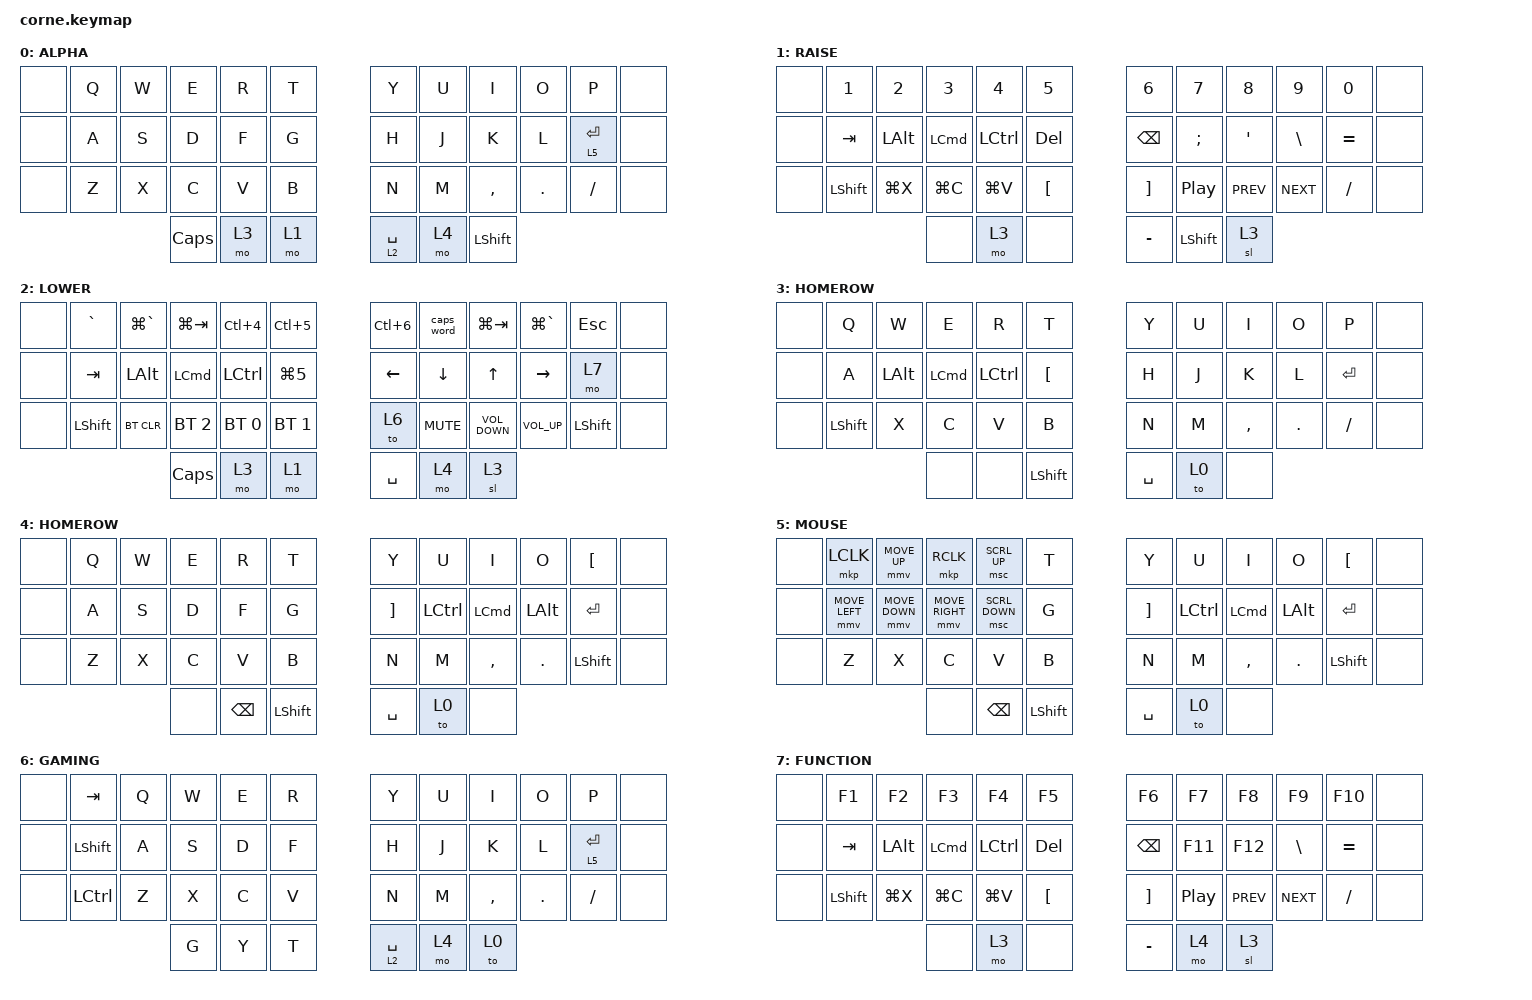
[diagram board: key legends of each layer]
#include <behaviors.dtsi>
#include <dt-bindings/zmk/keys.h>
#include <dt-bindings/zmk/bt.h>

#define ZMK_POINTING_DEFAULT_MOVE_VAL 1500  // default: 600
#define ZMK_POINTING_DEFAULT_SCRL_VAL 20
#include <dt-bindings/zmk/pointing.h>
#include <dt-bindings/zmk/ext_power.h>

#define L0 0
#define L1 1
#define L2 2
#define L3 3
#define L4 4
#define L5 5
#define L6 6
#define L7 7

#define KEYS_L 0 1 2 3 4 5 12 13 14 15 16 17 24 25 26 27 28 29 36 37 38
#define KEYS_R 6 7 8 9 10 11 18 19 20 21 22 23 30 31 32 33 34 35 39 40 41

/ { 
  keymap {
    compatible = "zmk,keymap";

    /**
     * Alpha layer (L0)
     */
    layer_0 {
      label = "ALPHA";
      bindings = <
        &none &kp Q     &kp W       &kp E       &kp R        &kp T       &kp Y      &kp U        &kp I       &kp O       &kp P     &none
        &none &kp A     &kp S       &kp D       &kp F        &kp G       &kp H      &kp J        &kp K       &kp L       &lt L5 RET   &none
        &none &kp Z     &kp X       &kp C       &kp V        &kp B       &kp N      &kp M        &kp COMMA   &kp DOT     &kp FSLH  &none
                                    &kp CAPS    &mo L3       &mo L1      &lt L2 SPACE &mo L4  &kp LSHIFT
      >;
    };

    /**
     * Symbols layer (L1)
     */
    layer_1 {
      label = "RAISE";
      bindings = <
        &none &kp N1   &kp N2    &kp N3    &kp N4     &kp N5     &kp N6    &kp N7    &kp N8    &kp N9            &kp N0    &none
        &none &kp TAB  &kp LALT  &kp LCMD  &kp LCTRL  &kp DEL   &kp BSPC  &kp SEMI  &kp SQT   &kp BSLH      &kp EQUAL &none
        &none &kp LSHIFT &kp LG(X) &kp LG(C) &kp LG(V)  &kp LBKT &kp RBKT  &kp C_PP &kp C_PREV  &kp C_NEXT &kp FSLH  &none
                                 &none     &mo L3     &none      &kp MINUS &kp LSHIFT  &sl L3
      >;
    };

    /**
     * Number and directions layer (L2)
     */
    layer_2 {
      label = "LOWER";
      bindings = <
        &none &kp GRAVE &kp LG(GRAVE)  &kp LG(TAB)  &kp LC(N4)  &kp LC(N5)  &kp LC(N6)  &caps_word &kp LG(TAB) &kp LG(GRAVE)  &kp ESC &none
        &none &kp TAB &kp LALT  &kp LCMD  &kp LCTRL  &kp LG(N5)  &kp LEFT &kp DOWN &kp UP  &kp RIGHT  &mo L7    &none
        &none &kp LSHIFT  &bt BT_CLR &bt BT_SEL 2  &bt BT_SEL 0  &bt BT_SEL 1   &to L6   &kp C_MUTE &kp C_VOLUME_DOWN &kp C_VOLUME_UP &kp LSHIFT  &none
                  &kp CAPS  &mo L3     &mo L1      &kp SPACE &mo L4       &sl L3
      >;
    };

    /**
     * Controls homerow mod (L3)
     */
    layer_3 {
      label = "HOMEROW";
      bindings = <
        &none &kp Q &kp W       &kp E       &kp R        &kp T       &kp Y &kp U        &kp I       &kp O       &kp P     &none
        &none &kp A &kp LALT    &kp LCMD    &kp LCTRL    &kp LBKT    &kp H &kp J &kp K  &kp L  &kp RET  &none
        &none &kp LSHFT  &kp X  &kp C  &kp V &kp B  &kp N &kp M &kp COMMA   &kp DOT  &kp SLASH &none
                            &none &none      &kp LSHFT      &kp SPACE  &to L0       &none
      >;
    };

    /**
     * Controls homerow mod (L4)
     */
    layer_4 {
      label = "HOMEROW";
      bindings = <
        &none &kp Q &kp W  &kp E  &kp R  &kp T        &kp Y &kp U        &kp I       &kp O       &kp LBKT   &none
        &none &kp A &kp S  &kp D  &kp F  &kp G        &kp RBKT &kp LCTRL &kp LCMD  &kp LALT  &kp RET  &none
        &none &kp Z &kp X  &kp C  &kp V  &kp B        &kp N &kp M &kp COMMA   &kp DOT  &kp LSHFT &none
                            &none &kp BSPC      &kp LSHFT      &kp SPACE  &to L0       &none
      >;
    };

    layer_5 {
      label = "MOUSE";
      bindings = <
        &none &mkp LCLK &mmv MOVE_UP  &mkp RCLK  &msc SCRL_UP  &kp T        &kp Y &kp U        &kp I       &kp O       &kp LBKT   &none
        &none &mmv MOVE_LEFT &mmv MOVE_DOWN  &mmv MOVE_RIGHT  &msc SCRL_DOWN  &kp G        &kp RBKT &kp LCTRL &kp LCMD  &kp LALT  &kp RET  
        &none&none &kp Z &kp X  &kp C  &kp V  &kp B        &kp N &kp M &kp COMMA   &kp DOT  &kp LSHFT &none
                            &none &kp BSPC      &kp LSHFT      &kp SPACE  &to L0       &none
      >;
    };

    /**
     * Gaming layer (L6)
     */
    layer_6 {
      label = "GAMING";
      bindings = <
        &none &kp TAB     &kp Q       &kp W       &kp E        &kp R       &kp Y      &kp U        &kp I       &kp O       &kp P     &none
        &none &kp LSHIFT  &kp A       &kp S       &kp D        &kp F       &kp H      &kp J        &kp K       &kp L       &lt L5 RET   &none
        &none &kp LCTRL   &kp Z       &kp X       &kp C        &kp V       &kp N      &kp M        &kp COMMA   &kp DOT     &kp FSLH  &none
                                      &kp G       &kp Y        &kp T       &lt L2 SPACE &mo L4     &to L0
      >;
    };

    layer_7 {
      label = "FUNCTION";
      bindings = <
        &none &kp F1   &kp F2    &kp F3    &kp F4     &kp F5     &kp F6    &kp F7    &kp F8    &kp F9       &kp F10    &none
        &none &kp TAB  &kp LALT  &kp LCMD  &kp LCTRL  &kp DEL   &kp BSPC  &kp F11  &kp F12   &kp BSLH      &kp EQUAL &none
        &none &kp LSHIFT &kp LG(X) &kp LG(C) &kp LG(V)  &kp LBKT &kp RBKT  &kp C_PP &kp C_PREV  &kp C_NEXT &kp FSLH  &none
                                 &none     &mo L3     &none      &kp MINUS &mo L4    &sl L3
      >;
    };
  };
};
